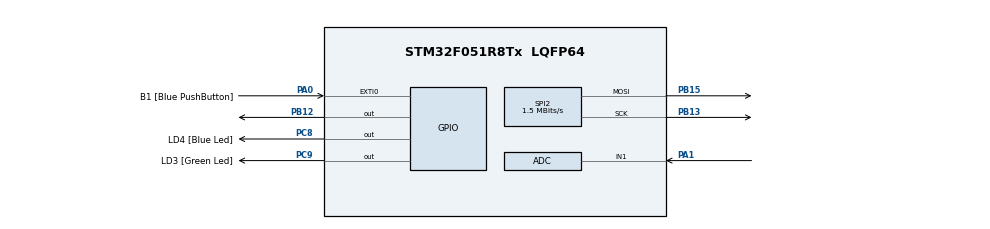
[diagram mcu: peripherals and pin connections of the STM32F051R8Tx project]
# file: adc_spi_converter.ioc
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Mcu.Family=STM32F0
Mcu.Name=STM32F051R8Tx
Mcu.Package=LQFP64
PA0.GPIO_Label=B1 [Blue PushButton]
PA0.GPIO_ModeDefaultEXTI=GPIO_MODE_EVT_RISING
PA0.Signal=GPXTI0
PA1.Mode=IN1
PA1.Signal=ADC_IN1
PA13.GPIO_Label=SWDIO
PA13.Mode=Serial_Wire
PA13.Signal=SYS_SWDIO
PA14.GPIO_Label=SWCLK
PA14.Mode=Serial_Wire
PA14.Signal=SYS_SWCLK
PB12.Signal=GPIO_Output
PB13.Mode=TX_Only_Simplex_Unidirect_Master
PB13.Signal=SPI2_SCK
PB15.Mode=TX_Only_Simplex_Unidirect_Master
PB15.Signal=SPI2_MOSI
PC8.GPIO_Label=LD4 [Blue Led]
PC8.Signal=GPIO_Output
PC9.GPIO_Label=LD3 [Green Led]
PC9.Signal=GPIO_Output
ProjectManager.HeapSize=0x200
ProjectManager.StackSize=0x400
ProjectManager.TargetToolchain=STM32CubeIDE
RCC.AHBFreq_Value=48000000
RCC.APB1Freq_Value=48000000
RCC.APB1TimFreq_Value=48000000
RCC.HCLKFreq_Value=48000000
RCC.PLLMUL=RCC_PLL_MUL12
RCC.SYSCLKFreq_VALUE=48000000
RCC.SYSCLKSource=RCC_SYSCLKSOURCE_PLLCLK
SPI2.BaudRatePrescaler=SPI_BAUDRATEPRESCALER_32
SPI2.CalculateBaudRate=1.5 MBits/s
SPI2.DataSize=SPI_DATASIZE_8BIT
SPI2.Direction=SPI_DIRECTION_2LINES
SPI2.Mode=SPI_MODE_MASTER
SPI2.VirtualType=VM_MASTER
board=STM32F0DISCOVERY

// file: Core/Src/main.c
/* USER CODE BEGIN Header */
/**
  ******************************************************************************
  * @file           : main.c
  * @brief          : Main program body
  ******************************************************************************
  * @attention
  *
  * <h2><center>&copy; Copyright (c) 2020 STMicroelectronics.
  * All rights reserved.</center></h2>
  *
  * This software component is licensed by ST under BSD 3-Clause license,
  * the "License"; You may not use this file except in compliance with the
  * License. You may obtain a copy of the License at:
  *                        opensource.org/licenses/BSD-3-Clause
  *
  ******************************************************************************
  */
/* USER CODE END Header */

#include "main.h"

void SystemClock_Config(void);
void MX_GPIO_Init(void);
void MX_ADC_Init(void);
void MX_SPI2_Init(void);

int main(void)
{

  /* MCU Configuration--------------------------------------------------------*/

  /* Reset of all peripherals, Initializes the Flash interface and the Systick. */

  LL_APB1_GRP2_EnableClock(LL_APB1_GRP2_PERIPH_SYSCFG);
  LL_APB1_GRP1_EnableClock(LL_APB1_GRP1_PERIPH_PWR);

  /* System interrupt init*/

  /* Configure the system clock */
  SystemClock_Config();

  /* Initialize all configured peripherals */
  MX_GPIO_Init();
  MX_ADC_Init();
  MX_SPI2_Init();
  /* USER CODE BEGIN 2 */
  LL_GPIO_SetOutputPin(GPIOB, LL_GPIO_PIN_12);
  /* USER CODE END 2 */

  /* Infinite loop */
  while (1)
  {
    adc_spi_convert();
  }
}

void SystemClock_Config(void)
{
  LL_FLASH_SetLatency(LL_FLASH_LATENCY_1);

  if(LL_FLASH_GetLatency() != LL_FLASH_LATENCY_1)
  {
  Error_Handler();
  }
  LL_RCC_HSI_Enable();

   /* Wait till HSI is ready */
  while(LL_RCC_HSI_IsReady() != 1)
  {

  }
  LL_RCC_HSI_SetCalibTrimming(16);
  LL_RCC_HSI14_Enable();

   /* Wait till HSI14 is ready */
  while(LL_RCC_HSI14_IsReady() != 1)
  {

  }
  LL_RCC_HSI14_SetCalibTrimming(16);
  LL_RCC_PLL_ConfigDomain_SYS(LL_RCC_PLLSOURCE_HSI_DIV_2, LL_RCC_PLL_MUL_12);
  LL_RCC_PLL_Enable();

   /* Wait till PLL is ready */
  while(LL_RCC_PLL_IsReady() != 1)
  {

  }
  LL_RCC_SetAHBPrescaler(LL_RCC_SYSCLK_DIV_1);
  LL_RCC_SetAPB1Prescaler(LL_RCC_APB1_DIV_1);
  LL_RCC_SetSysClkSource(LL_RCC_SYS_CLKSOURCE_PLL);

   /* Wait till System clock is ready */
  while(LL_RCC_GetSysClkSource() != LL_RCC_SYS_CLKSOURCE_STATUS_PLL)
  {

  }
  LL_Init1msTick(48000000);
  LL_SetSystemCoreClock(48000000);
  LL_RCC_HSI14_EnableADCControl();
}

void MX_ADC_Init(void)
{

  LL_ADC_InitTypeDef ADC_InitStruct = {0};
  LL_ADC_REG_InitTypeDef ADC_REG_InitStruct = {0};

  LL_GPIO_InitTypeDef GPIO_InitStruct = {0};

  /* Peripheral clock enable */
  LL_APB1_GRP2_EnableClock(LL_APB1_GRP2_PERIPH_ADC1);

  LL_AHB1_GRP1_EnableClock(LL_AHB1_GRP1_PERIPH_GPIOA);
  /**ADC GPIO Configuration
  PA1   ------> ADC_IN1
  */
  GPIO_InitStruct.Pin = LL_GPIO_PIN_1;
  GPIO_InitStruct.Mode = LL_GPIO_MODE_ANALOG;
  GPIO_InitStruct.Pull = LL_GPIO_PULL_NO;
  LL_GPIO_Init(GPIOA, &GPIO_InitStruct);

  /** Configure Regular Channel
  */
  LL_ADC_REG_SetSequencerChAdd(ADC1, LL_ADC_CHANNEL_1);
  /** Configure the global features of the ADC (Clock, Resolution, Data Alignment and number of conversion)
  */
  ADC_InitStruct.Clock = LL_ADC_CLOCK_ASYNC;
  ADC_InitStruct.Resolution = LL_ADC_RESOLUTION_12B;
  ADC_InitStruct.DataAlignment = LL_ADC_DATA_ALIGN_RIGHT;
  ADC_InitStruct.LowPowerMode = LL_ADC_LP_MODE_NONE;
  LL_ADC_Init(ADC1, &ADC_InitStruct);
  ADC_REG_InitStruct.TriggerSource = LL_ADC_REG_TRIG_SOFTWARE;
  ADC_REG_InitStruct.SequencerDiscont = LL_ADC_REG_SEQ_DISCONT_DISABLE;
  ADC_REG_InitStruct.ContinuousMode = LL_ADC_REG_CONV_SINGLE;
  ADC_REG_InitStruct.DMATransfer = LL_ADC_REG_DMA_TRANSFER_LIMITED;
  ADC_REG_InitStruct.Overrun = LL_ADC_REG_OVR_DATA_PRESERVED;
  LL_ADC_REG_Init(ADC1, &ADC_REG_InitStruct);
  LL_ADC_REG_SetSequencerScanDirection(ADC1, LL_ADC_REG_SEQ_SCAN_DIR_FORWARD);
  LL_ADC_SetSamplingTimeCommonChannels(ADC1, LL_ADC_SAMPLINGTIME_1CYCLE_5);
  LL_ADC_DisableIT_EOC(ADC1);
  LL_ADC_DisableIT_EOS(ADC1);
  /* USER CODE BEGIN ADC_Init 2 */
  LL_ADC_StartCalibration(ADC1);
  while(LL_ADC_IsCalibrationOnGoing(ADC1));
  LL_ADC_Enable(ADC1);
  while(LL_ADC_IsActiveFlag_ADRDY(ADC1) == 0);
  /* USER CODE END ADC_Init 2 */

}

void MX_SPI2_Init(void)
{

  LL_SPI_InitTypeDef SPI_InitStruct = {0};

  LL_GPIO_InitTypeDef GPIO_InitStruct = {0};

  /* Peripheral clock enable */
  LL_APB1_GRP1_EnableClock(LL_APB1_GRP1_PERIPH_SPI2);

  LL_AHB1_GRP1_EnableClock(LL_AHB1_GRP1_PERIPH_GPIOB);
  /**SPI2 GPIO Configuration
  PB13   ------> SPI2_SCK
  PB15   ------> SPI2_MOSI
  */
  GPIO_InitStruct.Pin = LL_GPIO_PIN_13;
  GPIO_InitStruct.Mode = LL_GPIO_MODE_ALTERNATE;
  GPIO_InitStruct.Speed = LL_GPIO_SPEED_FREQ_HIGH;
  GPIO_InitStruct.OutputType = LL_GPIO_OUTPUT_PUSHPULL;
  GPIO_InitStruct.Pull = LL_GPIO_PULL_NO;
  GPIO_InitStruct.Alternate = LL_GPIO_AF_0;
  LL_GPIO_Init(GPIOB, &GPIO_InitStruct);

  GPIO_InitStruct.Pin = LL_GPIO_PIN_15;
  GPIO_InitStruct.Mode = LL_GPIO_MODE_ALTERNATE;
  GPIO_InitStruct.Speed = LL_GPIO_SPEED_FREQ_HIGH;
  GPIO_InitStruct.OutputType = LL_GPIO_OUTPUT_PUSHPULL;
  GPIO_InitStruct.Pull = LL_GPIO_PULL_NO;
  GPIO_InitStruct.Alternate = LL_GPIO_AF_0;
  LL_GPIO_Init(GPIOB, &GPIO_InitStruct);

  /* SPI2 parameter configuration*/
  SPI_InitStruct.TransferDirection = LL_SPI_FULL_DUPLEX;
  SPI_InitStruct.Mode = LL_SPI_MODE_MASTER;
  SPI_InitStruct.DataWidth = LL_SPI_DATAWIDTH_8BIT;
  SPI_InitStruct.ClockPolarity = LL_SPI_POLARITY_LOW;
  SPI_InitStruct.ClockPhase = LL_SPI_PHASE_1EDGE;
  SPI_InitStruct.NSS = LL_SPI_NSS_SOFT;
  SPI_InitStruct.BaudRate = LL_SPI_BAUDRATEPRESCALER_DIV32;
  SPI_InitStruct.BitOrder = LL_SPI_MSB_FIRST;
  SPI_InitStruct.CRCCalculation = LL_SPI_CRCCALCULATION_DISABLE;
  SPI_InitStruct.CRCPoly = 7;
  LL_SPI_Init(SPI2, &SPI_InitStruct);
  LL_SPI_SetStandard(SPI2, LL_SPI_PROTOCOL_MOTOROLA);
  LL_SPI_EnableNSSPulseMgt(SPI2);
  /* USER CODE BEGIN SPI2_Init 2 */
  LL_SPI_Enable(SPI2);
  /* USER CODE END SPI2_Init 2 */

}

void MX_GPIO_Init(void)
{
  LL_EXTI_InitTypeDef EXTI_InitStruct = {0};
  LL_GPIO_InitTypeDef GPIO_InitStruct = {0};

  /* GPIO Ports Clock Enable */
  LL_AHB1_GRP1_EnableClock(LL_AHB1_GRP1_PERIPH_GPIOA);
  LL_AHB1_GRP1_EnableClock(LL_AHB1_GRP1_PERIPH_GPIOB);
  LL_AHB1_GRP1_EnableClock(LL_AHB1_GRP1_PERIPH_GPIOC);

  /**/
  LL_GPIO_ResetOutputPin(GPIOB, LL_GPIO_PIN_12);

  /**/
  LL_GPIO_ResetOutputPin(LD4_GPIO_Port, LD4_Pin);

  /**/
  LL_GPIO_ResetOutputPin(LD3_GPIO_Port, LD3_Pin);

  /**/
  LL_SYSCFG_SetEXTISource(LL_SYSCFG_EXTI_PORTA, LL_SYSCFG_EXTI_LINE0);

  /**/
  LL_GPIO_SetPinPull(B1_GPIO_Port, B1_Pin, LL_GPIO_PULL_NO);

  /**/
  LL_GPIO_SetPinMode(B1_GPIO_Port, B1_Pin, LL_GPIO_MODE_INPUT);

  /**/
  EXTI_InitStruct.Line_0_31 = LL_EXTI_LINE_0;
  EXTI_InitStruct.LineCommand = ENABLE;
  EXTI_InitStruct.Mode = LL_EXTI_MODE_EVENT;
  EXTI_InitStruct.Trigger = LL_EXTI_TRIGGER_RISING;
  LL_EXTI_Init(&EXTI_InitStruct);

  /**/
  GPIO_InitStruct.Pin = LL_GPIO_PIN_12;
  GPIO_InitStruct.Mode = LL_GPIO_MODE_OUTPUT;
  GPIO_InitStruct.Speed = LL_GPIO_SPEED_FREQ_LOW;
  GPIO_InitStruct.OutputType = LL_GPIO_OUTPUT_PUSHPULL;
  GPIO_InitStruct.Pull = LL_GPIO_PULL_NO;
  LL_GPIO_Init(GPIOB, &GPIO_InitStruct);

  /**/
  GPIO_InitStruct.Pin = LD4_Pin;
  GPIO_InitStruct.Mode = LL_GPIO_MODE_OUTPUT;
  GPIO_InitStruct.Speed = LL_GPIO_SPEED_FREQ_LOW;
  GPIO_InitStruct.OutputType = LL_GPIO_OUTPUT_PUSHPULL;
  GPIO_InitStruct.Pull = LL_GPIO_PULL_NO;
  LL_GPIO_Init(LD4_GPIO_Port, &GPIO_InitStruct);

  /**/
  GPIO_InitStruct.Pin = LD3_Pin;
  GPIO_InitStruct.Mode = LL_GPIO_MODE_OUTPUT;
  GPIO_InitStruct.Speed = LL_GPIO_SPEED_FREQ_LOW;
  GPIO_InitStruct.OutputType = LL_GPIO_OUTPUT_PUSHPULL;
  GPIO_InitStruct.Pull = LL_GPIO_PULL_NO;
  LL_GPIO_Init(LD3_GPIO_Port, &GPIO_InitStruct);

}

void Error_Handler(void)
{
}

/************************ (C) COPYRIGHT STMicroelectronics *****END OF FILE****/
